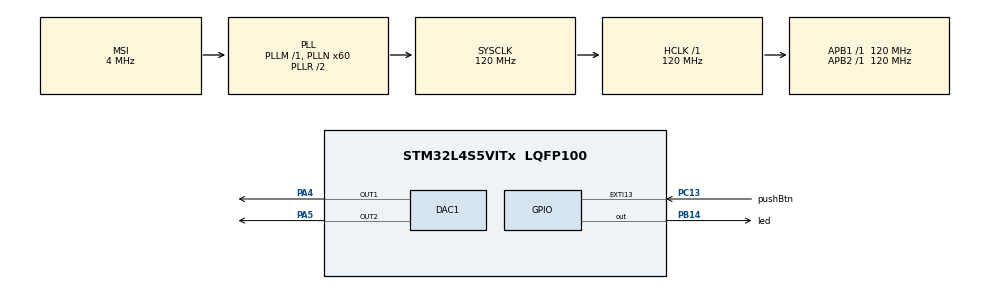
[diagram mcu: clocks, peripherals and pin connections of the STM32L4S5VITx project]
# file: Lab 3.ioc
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DAC1.DAC_Channel-DAC_OUT2=DAC_CHANNEL_2
Mcu.Family=STM32L4
Mcu.Name=STM32L4S5VITx
Mcu.Package=LQFP100
NVIC.EXTI15_10_IRQn=true\:0\:0\:false\:false\:true\:true\:true\:true
NVIC.PriorityGroup=NVIC_PRIORITYGROUP_4
NVIC.TIM2_IRQn=true\:0\:0\:false\:false\:true\:true\:true\:true
PA4.Signal=COMP_DAC11_group
PA5.Signal=COMP_DAC12_group
PB14.GPIO_Label=led
PB14.Signal=GPIO_Output
PC13.GPIO_Label=pushBtn
PC13.Signal=GPXTI13
ProjectManager.HeapSize=0x200
ProjectManager.StackSize=0x400
ProjectManager.TargetToolchain=STM32CubeIDE
RCC.ADCFreq_Value=48000000
RCC.AHBFreq_Value=120000000
RCC.APB1Freq_Value=120000000
RCC.APB1TimFreq_Value=120000000
RCC.APB2Freq_Value=120000000
RCC.APB2TimFreq_Value=120000000
RCC.CortexFreq_Value=120000000
RCC.HCLKFreq_Value=120000000
RCC.HSE_VALUE=8000000
RCC.HSI48_VALUE=48000000
RCC.HSI_VALUE=16000000
RCC.LSE_VALUE=32768
RCC.MSI_VALUE=4000000
RCC.PLLN=60
RCC.PLLSAI1N=24
RCC.SYSCLKFreq_VALUE=120000000
RCC.SYSCLKSource=RCC_SYSCLKSOURCE_PLLCLK
RCC.USBFreq_Value=48000000
RCC.VCOOutputFreq_Value=240000000
SH.COMP_DAC11_group.0=DAC1_OUT1,DAC_OUT1
SH.COMP_DAC12_group.0=DAC1_OUT2,DAC_OUT2
TIM2.Period=60000
TIM2.TIM_MasterOutputTrigger=TIM_TRGO_UPDATE
VP_TIM2_VS_ClockSourceINT.Mode=Internal
board=B-L4S5I-IOT01A

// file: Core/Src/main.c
/* USER CODE BEGIN Header */
/**
  ******************************************************************************
  * @file           : main.c
  * @brief          : Main program body
  ******************************************************************************
  * @attention
  *
  * Copyright (c) 2025 STMicroelectronics.
  * All rights reserved.
  *
  * This software is licensed under terms that can be found in the LICENSE file
  * in the root directory of this software component.
  * If no LICENSE file comes with this software, it is provided AS-IS.
  *
  ******************************************************************************
  */
/* USER CODE END Header */
#include "main.h"

/* USER CODE BEGIN Includes */
#include <math.h>
#include "arm_math.h"
/* USER CODE END Includes */

/* USER CODE BEGIN PD */
#define WAVE_SAMPLES 8
#define SIN_SAMPLES 441
#define C6 1046.50
#define E6 1318.51
#define G6 1567.98

/* USER CODE END PD */

DAC_HandleTypeDef hdac1;

TIM_HandleTypeDef htim2;
DMA_HandleTypeDef hdma_tim2_up;

/* USER CODE BEGIN PV */
uint8_t wave_index;  // Tracks active waveform
uint8_t triangle_wave[WAVE_SAMPLES];
uint8_t sawtooth_wave[WAVE_SAMPLES];
uint8_t sinusoid_wave[WAVE_SAMPLES];
unit8_t sine_wave[SIN_SAMPLES];
uint32_t TIMindex;

/* USER CODE END PV */

void SystemClock_Config(void);
static void MX_GPIO_Init(void);
static void MX_DMA_Init(void);
static void MX_DAC1_Init(void);
static void MX_TIM2_Init(void);

/* USER CODE BEGIN 0 */
void generate_sine_wave(float frequency)
{
    for (int i = 0; i < SIN_SAMPLES; i++)
    {
        // Calculate the sine wave value for each sample
        // sine_wave[i] = sin(2 * pi * frequency * i / sampling_rate)
        sine_wave[i] = (arm_sin_f32(2 * M_PI * frequency * i / SAMPLING_RATE) + 1) * 127;  // Scaled for 8-bit DAC
    }
}

/* USER CODE END 0 */

int main(void)
{

  /* USER CODE BEGIN 1 */
	wave_index = 0;
    TIMindex = 0;  // Static index to keep track of the sine wave sample

  /* USER CODE END 1 */

  /* MCU Configuration--------------------------------------------------------*/

  /* Reset of all peripherals, Initializes the Flash interface and the Systick. */
  HAL_Init();

  /* Configure the system clock */
  SystemClock_Config();

  /* Initialize all configured peripherals */
  MX_GPIO_Init();
  MX_DMA_Init();
  MX_DAC1_Init();
  MX_TIM2_Init();
  /* USER CODE BEGIN 2 */

  // Using 8-bit waves -> Max DAC Output = 2^8 - 1 = 255
  uint8_t sawtooth_multipliers[8] = {0, 1, 2, 3, 4, 5, 6, 7};
  uint8_t triangle_multipliers[8] = {0, 1, 2, 3, 3, 2, 1, 0};
  float   sinusoid_multiplier[8]  = {0.0f, 0.707f, 1.0f, 0.707f, 0.0f, -0.707f, -1.0f, -0.707f};

  for (int i = 0; i < 8; i++) {
	  // 7 and 3 are picked because largest values mapped to 255
	  // smallest multiplier (0) mapped to 0 in dac output
	  sawtooth_wave[i] = 255 * sawtooth_multipliers[i] / 7;
	  triangle_wave[i] = 255 * triangle_multipliers[i] / 3;
	  // By adding 1, we make the wave oscillate between [0, 2] instead of [-1,1]
	  // then we multiply and scale. Since 255 is largest, we divide everything
	  // by 2 which is equivalent to multiplying by half of 255
	  sinusoid_wave[i] = (uint8_t)((sinusoid_multiplier[i] + 1.0f) * 127.5f);
  }

  uint8_t dac_triangle, dac_sawtooth, dac_sinusoid;
  /* USER CODE END 2 */

  /* Infinite loop */
  while (1)
  {

    /* USER CODE BEGIN 3 */
	  int i = 0;
	  HAL_DAC_Start(&hdac1, DAC_CHANNEL_1);
	  HAL_DAC_Start(&hdac1, DAC_CHANNEL_2);

	  for (int j = 0; j < 3000; j++){
		  dac_triangle = triangle_wave[i];
	  	  dac_sawtooth = sawtooth_wave[i];
	  	  dac_sinusoid = sinusoid_wave[i];
	  	  HAL_DAC_SetValue(&hdac1, DAC_CHANNEL_1, DAC_ALIGN_8B_R, dac_sinusoid);
	  	  HAL_DAC_SetValue(&hdac1, DAC_CHANNEL_2, DAC_ALIGN_8B_R, dac_triangle);
	  	  // index for next value but mod 8 -> wrap around saw/tri wave arrays
	  	  i = (i + 1) % 8;
	  	  // to have 65Hz -> 15ms per period
	  	  // delay between each increment must be around 2ms
	  	  // because 8 data points for each period, and each period = 15ms
	  	  // -> 15/8 ~= 2ms
	  	  HAL_Delay(2);
	  }
	  HAL_DAC_Stop(&hdac1, DAC_CHANNEL_1);
	  HAL_DAC_Stop(&hdac1, DAC_CHANNEL_2);

	  int breakpoint = 0;

  }
  /* USER CODE END 3 */
}

void SystemClock_Config(void)
{
  RCC_OscInitTypeDef RCC_OscInitStruct = {0};
  RCC_ClkInitTypeDef RCC_ClkInitStruct = {0};

  /** Configure the main internal regulator output voltage
  */
  if (HAL_PWREx_ControlVoltageScaling(PWR_REGULATOR_VOLTAGE_SCALE1_BOOST) != HAL_OK)
  {
    Error_Handler();
  }

  /** Initializes the RCC Oscillators according to the specified parameters
  * in the RCC_OscInitTypeDef structure.
  */
  RCC_OscInitStruct.OscillatorType = RCC_OSCILLATORTYPE_MSI;
  RCC_OscInitStruct.MSIState = RCC_MSI_ON;
  RCC_OscInitStruct.MSICalibrationValue = 0;
  RCC_OscInitStruct.MSIClockRange = RCC_MSIRANGE_6;
  RCC_OscInitStruct.PLL.PLLState = RCC_PLL_ON;
  RCC_OscInitStruct.PLL.PLLSource = RCC_PLLSOURCE_MSI;
  RCC_OscInitStruct.PLL.PLLM = 1;
  RCC_OscInitStruct.PLL.PLLN = 60;
  RCC_OscInitStruct.PLL.PLLP = RCC_PLLP_DIV2;
  RCC_OscInitStruct.PLL.PLLQ = RCC_PLLQ_DIV2;
  RCC_OscInitStruct.PLL.PLLR = RCC_PLLR_DIV2;
  if (HAL_RCC_OscConfig(&RCC_OscInitStruct) != HAL_OK)
  {
    Error_Handler();
  }

  /** Initializes the CPU, AHB and APB buses clocks
  */
  RCC_ClkInitStruct.ClockType = RCC_CLOCKTYPE_HCLK|RCC_CLOCKTYPE_SYSCLK
                              |RCC_CLOCKTYPE_PCLK1|RCC_CLOCKTYPE_PCLK2;
  RCC_ClkInitStruct.SYSCLKSource = RCC_SYSCLKSOURCE_PLLCLK;
  RCC_ClkInitStruct.AHBCLKDivider = RCC_SYSCLK_DIV1;
  RCC_ClkInitStruct.APB1CLKDivider = RCC_HCLK_DIV1;
  RCC_ClkInitStruct.APB2CLKDivider = RCC_HCLK_DIV1;

  if (HAL_RCC_ClockConfig(&RCC_ClkInitStruct, FLASH_LATENCY_5) != HAL_OK)
  {
    Error_Handler();
  }
}

static void MX_DAC1_Init(void)
{

  DAC_ChannelConfTypeDef sConfig = {0};

  /** DAC Initialization
  */
  hdac1.Instance = DAC1;
  if (HAL_DAC_Init(&hdac1) != HAL_OK)
  {
    Error_Handler();
  }

  /** DAC channel OUT1 config
  */
  sConfig.DAC_SampleAndHold = DAC_SAMPLEANDHOLD_DISABLE;
  sConfig.DAC_Trigger = DAC_TRIGGER_NONE;
  sConfig.DAC_HighFrequency = DAC_HIGH_FREQUENCY_INTERFACE_MODE_ABOVE_80MHZ;
  sConfig.DAC_OutputBuffer = DAC_OUTPUTBUFFER_ENABLE;
  sConfig.DAC_ConnectOnChipPeripheral = DAC_CHIPCONNECT_DISABLE;
  sConfig.DAC_UserTrimming = DAC_TRIMMING_FACTORY;
  if (HAL_DAC_ConfigChannel(&hdac1, &sConfig, DAC_CHANNEL_1) != HAL_OK)
  {
    Error_Handler();
  }

  /** DAC channel OUT2 config
  */
  if (HAL_DAC_ConfigChannel(&hdac1, &sConfig, DAC_CHANNEL_2) != HAL_OK)
  {
    Error_Handler();
  }

}

static void MX_TIM2_Init(void)
{

  TIM_ClockConfigTypeDef sClockSourceConfig = {0};
  TIM_MasterConfigTypeDef sMasterConfig = {0};

  htim2.Instance = TIM2;
  htim2.Init.Prescaler = 0;
  htim2.Init.CounterMode = TIM_COUNTERMODE_UP;
  htim2.Init.Period = 1814;
  htim2.Init.ClockDivision = TIM_CLOCKDIVISION_DIV1;
  htim2.Init.AutoReloadPreload = TIM_AUTORELOAD_PRELOAD_DISABLE;
  if (HAL_TIM_Base_Init(&htim2) != HAL_OK)
  {
    Error_Handler();
  }
  sClockSourceConfig.ClockSource = TIM_CLOCKSOURCE_INTERNAL;
  if (HAL_TIM_ConfigClockSource(&htim2, &sClockSourceConfig) != HAL_OK)
  {
    Error_Handler();
  }
  sMasterConfig.MasterOutputTrigger = TIM_TRGO_UPDATE;
  sMasterConfig.MasterSlaveMode = TIM_MASTERSLAVEMODE_DISABLE;
  if (HAL_TIMEx_MasterConfigSynchronization(&htim2, &sMasterConfig) != HAL_OK)
  {
    Error_Handler();
  }

}

static void MX_DMA_Init(void)
{

  /* DMA controller clock enable */
  __HAL_RCC_DMAMUX1_CLK_ENABLE();
  __HAL_RCC_DMA1_CLK_ENABLE();

  /* DMA interrupt init */
  /* DMA1_Channel1_IRQn interrupt configuration */
  HAL_NVIC_SetPriority(DMA1_Channel1_IRQn, 0, 0);
  HAL_NVIC_EnableIRQ(DMA1_Channel1_IRQn);

}

static void MX_GPIO_Init(void)
{
  GPIO_InitTypeDef GPIO_InitStruct = {0};

  /* GPIO Ports Clock Enable */
  __HAL_RCC_GPIOC_CLK_ENABLE();
  __HAL_RCC_GPIOA_CLK_ENABLE();

  /*Configure GPIO pin : UserBtn_Pin */
  GPIO_InitStruct.Pin = UserBtn_Pin;
  GPIO_InitStruct.Mode = GPIO_MODE_IT_RISING;
  GPIO_InitStruct.Pull = GPIO_NOPULL;
  HAL_GPIO_Init(UserBtn_GPIO_Port, &GPIO_InitStruct);

  /* EXTI interrupt init*/
  HAL_NVIC_SetPriority(EXTI15_10_IRQn, 0, 0);
  HAL_NVIC_EnableIRQ(EXTI15_10_IRQn);

}

/* USER CODE BEGIN 4 */
void HAL_GPIO_EXTI_Callback(unint16_t GPIO_Pin){
	if (GPIO_Pin == UserBtn_Pin){
		switch (wave_index){
            case 0:
                current_waveform = sawtooth_wave;
                wave_index = 1;
                break;
            case 1:
                current_waveform = sinusoid_wave;
                wave_index = 2;
                break;
            case 2:
                current_waveform = triangle_wave;
                wave_index = 0;
                break;
	}
	HAL_DAC_Start_DMA(&hdac, DAC_CHANNEL_1, (uint32_t*)sine_wave, SIN_SAMPLES, DAC_ALIGN_8B_R);

	}
}

void HAL_TIM_PeriodElapsedCallback(TIM_HandleTypeDef *htim)
{
    if(htim->Instance == TIM2)
    {
        // Assuming sine_wave is an array of DAC values
        HAL_DAC_SetValue(&hdac, DAC_CHANNEL_1, DAC_ALIGN_8B_R, sine_wave[TIMindex]);
        TIMindex = (TIMindex + 1) % (SINE_WAVE_SIZE)
    }
}

/* USER CODE END 4 */

void Error_Handler(void)
{
  __disable_irq();
  while (1)
  {
  }
}
